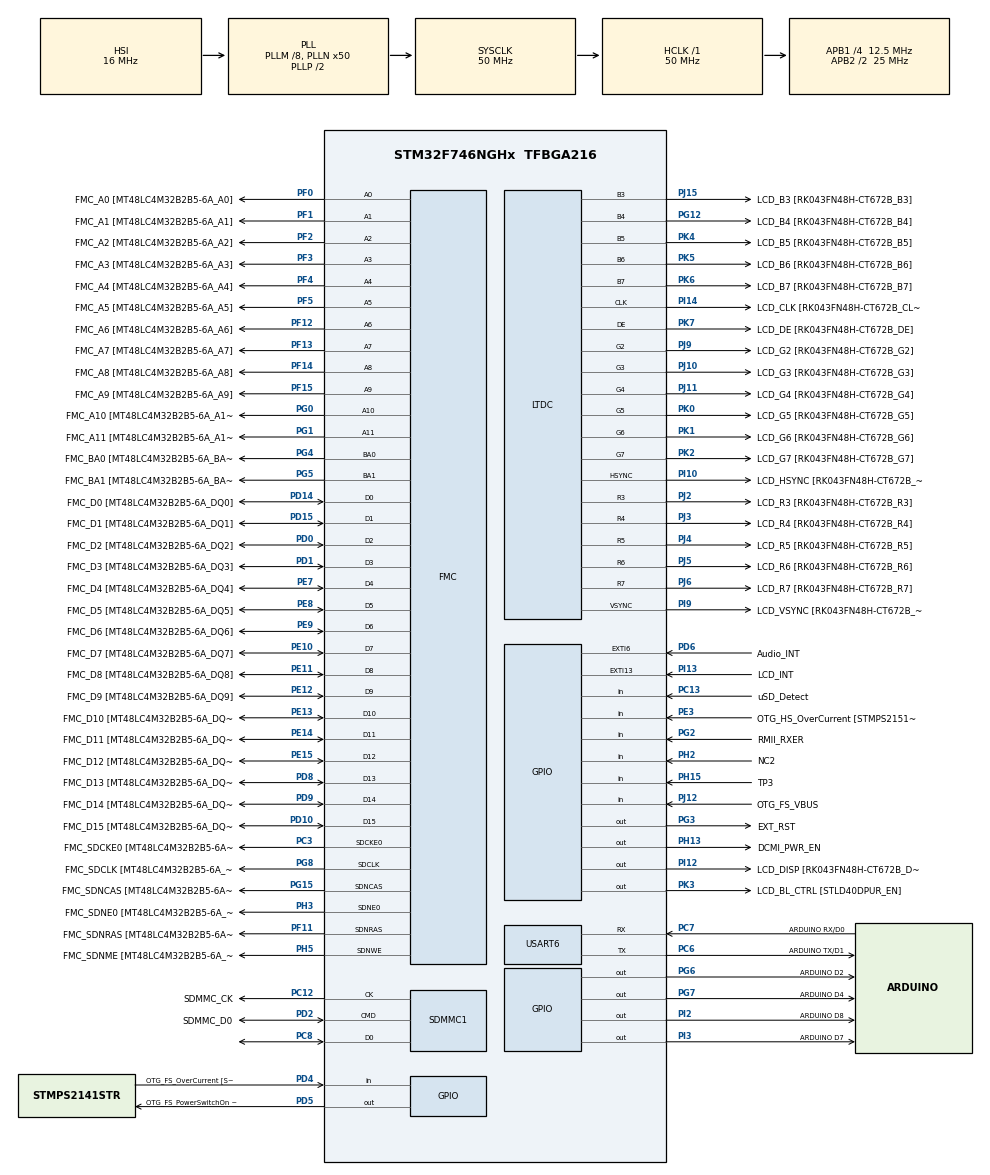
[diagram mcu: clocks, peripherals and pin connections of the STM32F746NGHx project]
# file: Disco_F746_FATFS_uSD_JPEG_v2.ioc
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Dma.Request0=SDMMC1_RX
Dma.Request1=SDMMC1_TX
Dma.SDMMC1_RX.0.Direction=DMA_PERIPH_TO_MEMORY
Dma.SDMMC1_RX.0.FIFOMode=DMA_FIFOMODE_ENABLE
Dma.SDMMC1_RX.0.FIFOThreshold=DMA_FIFO_THRESHOLD_FULL
Dma.SDMMC1_RX.0.Instance=DMA2_Stream3
Dma.SDMMC1_RX.0.MemBurst=DMA_MBURST_INC4
Dma.SDMMC1_RX.0.MemDataAlignment=DMA_MDATAALIGN_WORD
Dma.SDMMC1_RX.0.MemInc=DMA_MINC_ENABLE
Dma.SDMMC1_RX.0.Mode=DMA_PFCTRL
Dma.SDMMC1_RX.0.PeriphBurst=DMA_PBURST_INC4
Dma.SDMMC1_RX.0.PeriphDataAlignment=DMA_PDATAALIGN_WORD
Dma.SDMMC1_RX.0.PeriphInc=DMA_PINC_DISABLE
Dma.SDMMC1_RX.0.Priority=DMA_PRIORITY_LOW
Dma.SDMMC1_TX.1.Direction=DMA_MEMORY_TO_PERIPH
Dma.SDMMC1_TX.1.FIFOMode=DMA_FIFOMODE_ENABLE
Dma.SDMMC1_TX.1.FIFOThreshold=DMA_FIFO_THRESHOLD_FULL
Dma.SDMMC1_TX.1.Instance=DMA2_Stream6
Dma.SDMMC1_TX.1.MemBurst=DMA_MBURST_INC4
Dma.SDMMC1_TX.1.MemDataAlignment=DMA_MDATAALIGN_WORD
Dma.SDMMC1_TX.1.MemInc=DMA_MINC_ENABLE
Dma.SDMMC1_TX.1.Mode=DMA_PFCTRL
Dma.SDMMC1_TX.1.PeriphBurst=DMA_PBURST_INC4
Dma.SDMMC1_TX.1.PeriphDataAlignment=DMA_PDATAALIGN_WORD
Dma.SDMMC1_TX.1.PeriphInc=DMA_PINC_DISABLE
Dma.SDMMC1_TX.1.Priority=DMA_PRIORITY_LOW
FATFS.BSP.number=1
FATFS.USE_DMA_CODE_SD=1
FATFS0.BSP.STBoard=false
FATFS0.BSP.api=Unknown
FATFS0.BSP.instance=PC13
FATFS0.BSP.ip=GPIO
FATFS0.BSP.mode=Input
FATFS0.BSP.name=Detect_SDIO
FATFS0.BSP.solution=PC13
FMC.CASLatency1=FMC_SDRAM_CAS_LATENCY_3
FMC.ExitSelfRefreshDelay1=7
FMC.LoadToActiveDelay1=2
FMC.RCDDelay1=2
FMC.RPDelay1=2
FMC.RPDelay2=2
FMC.ReadBurst1=FMC_SDRAM_RBURST_ENABLE
FMC.ReadBurst2=FMC_SDRAM_RBURST_ENABLE
FMC.RowCycleDelay1=7
FMC.RowCycleDelay2=7
FMC.SDClockPeriod1=FMC_SDRAM_CLOCK_PERIOD_2
FMC.SDClockPeriod2=FMC_SDRAM_CLOCK_PERIOD_2
FMC.SelfRefreshTime1=4
FMC.WriteRecoveryTime1=3
Mcu.Family=STM32F7
Mcu.Name=STM32F746NGHx
Mcu.Package=TFBGA216
NVIC.DMA2_Stream3_IRQn=true\:0\:0\:false\:false\:true\:false\:true\:true
NVIC.DMA2_Stream6_IRQn=true\:0\:0\:false\:false\:true\:false\:true\:true
NVIC.PriorityGroup=NVIC_PRIORITYGROUP_4
NVIC.SDMMC1_IRQn=true\:0\:0\:false\:false\:true\:true\:true\:true
PA0/WKUP.GPIO_Label=ARDUINO A0
PA0/WKUP.GPIO_Mode=GPIO_MODE_ANALOG
PA0/WKUP.GPIO_PuPd=GPIO_NOPULL
PA0/WKUP.Signal=ADCx_IN0
PA1.GPIO_Label=RMII_REF_CLK [LAN8742A-CZ-TR_REFCLK0]
PA1.Signal=ETH_REF_CLK
PA10.GPIO_Label=OTG_FS_ID
PA10.Signal=USB_OTG_FS_ID
PA11.GPIO_Label=OTG_FS_N
PA11.Signal=USB_OTG_FS_DM
PA12.GPIO_Label=OTG_FS_P
PA12.Signal=USB_OTG_FS_DP
PA13.GPIO_Label=SWDIO
PA13.Signal=SYS_JTMS-SWDIO
PA14.GPIO_Label=SWCLK
PA14.Signal=SYS_JTCK-SWCLK
PA15.GPIO_Label=ARDUINO PWM/D9
PA15.GPIO_ModeDefaultPP=GPIO_MODE_AF_PP
PA15.GPIO_PuPd=GPIO_NOPULL
PA15.GPIO_Speed=GPIO_SPEED_FREQ_LOW
PA15.Signal=S_TIM2_CH1_ETR
PA2.GPIO_Label=RMII_MDIO [LAN8742A-CZ-TR_MDIO]
PA2.Signal=ETH_MDIO
PA3.GPIO_Label=ULPI_D0 [USB3320C-EZK_D0]
PA3.Signal=USB_OTG_HS_ULPI_D0
PA4.GPIO_Label=DCMI_HSYNC
PA4.Signal=DCMI_HSYNC
PA5.GPIO_Label=ULPI_CLK [USB3320C-EZK_CLKOUT]
PA5.Signal=USB_OTG_HS_ULPI_CK
PA6.Signal=DCMI_PIXCLK
PA7.GPIO_Label=RMII_CRS_DV [LAN8742A-CZ-TR_CRS_DV]
PA7.Signal=ETH_CRS_DV
PA8.GPIO_Label=ARDUINO PWM/D10
PA8.GPIO_ModeDefaultPP=GPIO_MODE_AF_PP
PA8.GPIO_PuPd=GPIO_NOPULL
PA8.GPIO_Speed=GPIO_SPEED_FREQ_LOW
PA8.Signal=S_TIM1_CH1
PA9.GPIO_Label=VCP_TX [STM32F103CBT6_PA3]
PA9.GPIO_Mode=GPIO_MODE_AF_PP
PA9.GPIO_PuPd=GPIO_NOPULL
PA9.GPIO_Speed=GPIO_SPEED_FREQ_LOW
PA9.Signal=USART1_TX
PB0.GPIO_Label=ULPI_D1 [USB3320C-EZK_D1]
PB0.Signal=USB_OTG_HS_ULPI_D1
PB1.GPIO_Label=ULPI_D2 [USB3320C-EZK_D2]
PB1.Signal=USB_OTG_HS_ULPI_D2
PB10.GPIO_Label=ULPI_D3 [USB3320C-EZK_D3]
PB10.Signal=USB_OTG_HS_ULPI_D3
PB11.GPIO_Label=ULPI_D4 [USB3320C-EZK_D4]
PB11.Signal=USB_OTG_HS_ULPI_D4
PB12.GPIO_Label=ULPI_D5 [USB3320C-EZK_D5]
PB12.Signal=USB_OTG_HS_ULPI_D5
PB13.GPIO_Label=ULPI_D6 [USB3320C-EZK_D6]
PB13.Signal=USB_OTG_HS_ULPI_D6
PB14.GPIO_Label=ARDUINO MISO/D12
PB14.GPIO_Mode=GPIO_MODE_AF_PP
PB14.GPIO_PuPd=GPIO_NOPULL
PB14.GPIO_Speed=GPIO_SPEED_FREQ_LOW
PB14.Signal=SPI2_MISO
PB15.GPIO_Label=ARDUINO MOSI/PWM/D11
PB15.GPIO_Mode=GPIO_MODE_AF_PP
PB15.GPIO_PuPd=GPIO_NOPULL
PB15.GPIO_Speed=GPIO_SPEED_FREQ_LOW
PB15.Signal=SPI2_MOSI
PB2.Signal=QUADSPI_CLK
PB3.GPIO_Label=SWO
PB3.Signal=SYS_JTDO-SWO
PB4.GPIO_Label=ARDUINO PWM/D3
PB4.GPIO_ModeDefaultPP=GPIO_MODE_AF_PP
PB4.GPIO_PuPd=GPIO_NOPULL
PB4.GPIO_Speed=GPIO_SPEED_FREQ_LOW
PB4.Signal=S_TIM3_CH1
PB5.GPIO_Label=ULPI_D7 [USB3320C-EZK_D7]
PB5.Signal=USB_OTG_HS_ULPI_D7
PB6.GPIO_Label=QSPI_NCS [N25Q128A13EF840E_S]
PB6.Signal=QUADSPI_BK1_NCS
PB7.GPIO_Label=VCP_RX [STM32F103CBT6_PA2]
PB7.GPIO_Mode=GPIO_MODE_AF_PP
PB7.GPIO_PuPd=GPIO_NOPULL
PB7.GPIO_Speed=GPIO_SPEED_FREQ_LOW
PB7.Signal=USART1_RX
PB8.GPIO_Label=ARDUINO SCL/D15
PB8.GPIO_Mode=GPIO_MODE_AF_OD
PB8.GPIO_PuPd=GPIO_NOPULL
PB8.GPIO_Speed=GPIO_SPEED_FREQ_LOW
PB8.Signal=I2C1_SCL
PB9.GPIO_Label=ARDUINO SDA/D14
PB9.GPIO_Mode=GPIO_MODE_AF_OD
PB9.GPIO_PuPd=GPIO_NOPULL
PB9.GPIO_Speed=GPIO_SPEED_FREQ_LOW
PB9.Signal=I2C1_SDA
PC0.GPIO_Label=ULPI_STP [USB3320C-EZK_STP]
PC0.Signal=USB_OTG_HS_ULPI_STP
PC1.GPIO_Label=RMII_MDC [LAN8742A-CZ-TR_MDC]
PC1.Signal=ETH_MDC
PC10.GPIO_Label=SDMMC_D2
PC10.Signal=SDMMC1_D2
PC11.GPIO_Label=SDMMC_D3
PC11.Signal=SDMMC1_D3
PC12.GPIO_Label=SDMMC_CK
PC12.GPIO_PuPd=GPIO_PULLUP
PC12.Mode=SD_1_bit
PC12.Signal=SDMMC1_CK
PC13.GPIO_Label=uSD_Detect
PC13.Signal=GPIO_Input
PC14/OSC32_IN.GPIO_Label=RCC_OSC32_IN
PC14/OSC32_IN.Signal=RCC_OSC32_IN
PC15/OSC32_OUT.GPIO_Label=RCC_OSC32_OUT
PC15/OSC32_OUT.Signal=RCC_OSC32_OUT
PC2.GPIO_Label=ULPI_DIR [USB3320C-EZK_DIR]
PC2.Signal=USB_OTG_HS_ULPI_DIR
PC3.GPIO_Label=FMC_SDCKE0 [MT48LC4M32B2B5-6A_CKE]
PC3.Mode=SdramChipSelect1_1
PC3.Signal=FMC_SDCKE0
PC4.GPIO_Label=RMII_RXD0 [LAN8742A-CZ-TR_RXD0]
PC4.Signal=ETH_RXD0
PC5.GPIO_Label=RMII_RXD1 [LAN8742A-CZ-TR_RXD1]
PC5.Signal=ETH_RXD1
PC6.GPIO_Label=ARDUINO TX/D1
PC6.Mode=Asynchronous
PC6.Signal=USART6_TX
PC7.GPIO_Label=ARDUINO RX/D0
PC7.Mode=Asynchronous
PC7.Signal=USART6_RX
PC8.GPIO_PuPd=GPIO_PULLUP
PC8.Mode=SD_1_bit
PC8.Signal=SDMMC1_D0
PC9.Signal=SDMMC1_D1
PD0.GPIO_Label=FMC_D2 [MT48LC4M32B2B5-6A_DQ2]
PD0.Signal=FMC_D2_DA2
PD1.GPIO_Label=FMC_D3 [MT48LC4M32B2B5-6A_DQ3]
PD1.Signal=FMC_D3_DA3
PD10.GPIO_Label=FMC_D15 [MT48LC4M32B2B5-6A_DQ15]
PD10.Signal=FMC_D15_DA15
PD11.GPIO_Label=QSPI_D0 [N25Q128A13EF840E_DQ0]
PD11.Signal=QUADSPI_BK1_IO0
PD12.GPIO_Label=QSPI_D1 [N25Q128A13EF840E_DQ1]
PD12.Signal=QUADSPI_BK1_IO1
PD13.GPIO_Label=QSPI_D3 [N25Q128A13EF840E_DQ3]
PD13.Signal=QUADSPI_BK1_IO3
PD14.GPIO_Label=FMC_D0 [MT48LC4M32B2B5-6A_DQ0]
PD14.Signal=FMC_D0_DA0
PD15.GPIO_Label=FMC_D1 [MT48LC4M32B2B5-6A_DQ1]
PD15.Signal=FMC_D1_DA1
PD2.GPIO_Label=SDMMC_D0
PD2.GPIO_PuPd=GPIO_PULLUP
PD2.Mode=SD_1_bit
PD2.Signal=SDMMC1_CMD
PD3.GPIO_Label=DCMI_D5
PD3.Signal=DCMI_D5
PD4.GPIO_Label=OTG_FS_OverCurrent [STMPS2141STR_Fault]
PD4.Signal=GPIO_Input
PD5.GPIO_Label=OTG_FS_PowerSwitchOn [STMPS2141STR_EN]
PD5.PinState=GPIO_PIN_SET
PD5.Signal=GPIO_Output
PD6.GPIO_Label=Audio_INT
PD6.GPIO_ModeDefaultEXTI=GPIO_MODE_EVT_RISING
PD6.Signal=GPXTI6
PD7.GPIO_Label=SPDIF_RX0 [74LVC1G04SE_4]
PD7.Signal=SPDIFRX_IN0
PD8.GPIO_Label=FMC_D13 [MT48LC4M32B2B5-6A_DQ13]
PD8.Signal=FMC_D13_DA13
PD9.GPIO_Label=FMC_D14 [MT48LC4M32B2B5-6A_DQ14]
PD9.Signal=FMC_D14_DA14
PE0.GPIO_Label=FMC_NBL0 [MT48LC4M32B2B5-6A_DQM0]
PE0.Signal=FMC_NBL0
PE1.GPIO_Label=FMC_NBL1 [MT48LC4M32B2B5-6A_DQM1]
PE1.Signal=FMC_NBL1
PE10.GPIO_Label=FMC_D7 [MT48LC4M32B2B5-6A_DQ7]
PE10.Signal=FMC_D7_DA7
PE11.GPIO_Label=FMC_D8 [MT48LC4M32B2B5-6A_DQ8]
PE11.Signal=FMC_D8_DA8
PE12.GPIO_Label=FMC_D9 [MT48LC4M32B2B5-6A_DQ9]
PE12.Signal=FMC_D9_DA9
PE13.GPIO_Label=FMC_D10 [MT48LC4M32B2B5-6A_DQ10]
PE13.Signal=FMC_D10_DA10
PE14.GPIO_Label=FMC_D11 [MT48LC4M32B2B5-6A_DQ11]
PE14.Signal=FMC_D11_DA11
PE15.GPIO_Label=FMC_D12 [MT48LC4M32B2B5-6A_DQ12]
PE15.Signal=FMC_D12_DA12
PE2.GPIO_Label=QSPI_D2 [N25Q128A13EF840E_DQ2]
PE2.Signal=QUADSPI_BK1_IO2
PE3.GPIO_Label=OTG_HS_OverCurrent [STMPS2151STR_FAULT]
PE3.Signal=GPIO_Input
PE4.GPIO_Label=LCD_B0 [RK043FN48H-CT672B_B0]
PE4.Signal=LTDC_B0
PE5.GPIO_Label=DCMI_D6
PE5.Signal=DCMI_D6
PE6.GPIO_Label=DCMI_D7
PE6.Signal=DCMI_D7
PE7.GPIO_Label=FMC_D4 [MT48LC4M32B2B5-6A_DQ4]
PE7.Signal=FMC_D4_DA4
PE8.GPIO_Label=FMC_D5 [MT48LC4M32B2B5-6A_DQ5]
PE8.Signal=FMC_D5_DA5
PE9.GPIO_Label=FMC_D6 [MT48LC4M32B2B5-6A_DQ6]
PE9.Signal=FMC_D6_DA6
PF0.GPIO_Label=FMC_A0 [MT48LC4M32B2B5-6A_A0]
PF0.Signal=FMC_A0
PF1.GPIO_Label=FMC_A1 [MT48LC4M32B2B5-6A_A1]
PF1.Signal=FMC_A1
PF10.GPIO_Label=ARDUINO A1
PF10.GPIO_Mode=GPIO_MODE_ANALOG
PF10.GPIO_PuPd=GPIO_NOPULL
PF10.Signal=ADC3_IN8
PF11.GPIO_Label=FMC_SDNRAS [MT48LC4M32B2B5-6A_RAS]
PF11.Signal=FMC_SDNRAS
PF12.GPIO_Label=FMC_A6 [MT48LC4M32B2B5-6A_A6]
PF12.Signal=FMC_A6
PF13.GPIO_Label=FMC_A7 [MT48LC4M32B2B5-6A_A7]
PF13.Signal=FMC_A7
PF14.GPIO_Label=FMC_A8 [MT48LC4M32B2B5-6A_A8]
PF14.Signal=FMC_A8
PF15.GPIO_Label=FMC_A9 [MT48LC4M32B2B5-6A_A9]
PF15.Signal=FMC_A9
PF2.GPIO_Label=FMC_A2 [MT48LC4M32B2B5-6A_A2]
PF2.Signal=FMC_A2
PF3.GPIO_Label=FMC_A3 [MT48LC4M32B2B5-6A_A3]
PF3.Signal=FMC_A3
PF4.GPIO_Label=FMC_A4 [MT48LC4M32B2B5-6A_A4]
PF4.Signal=FMC_A4
PF5.GPIO_Label=FMC_A5 [MT48LC4M32B2B5-6A_A5]
PF5.Signal=FMC_A5
PF6.GPIO_Label=ARDUINO A5
PF6.GPIO_Mode=GPIO_MODE_ANALOG
PF6.GPIO_PuPd=GPIO_NOPULL
PF6.Signal=ADC3_IN4
PF7.GPIO_Label=ARDUINO A4
PF7.GPIO_Mode=GPIO_MODE_ANALOG
PF7.GPIO_PuPd=GPIO_NOPULL
PF7.Signal=ADC3_IN5
PF8.GPIO_Label=ARDUINO A3
PF8.GPIO_Mode=GPIO_MODE_ANALOG
PF8.GPIO_PuPd=GPIO_NOPULL
PF8.Signal=ADC3_IN6
PF9.GPIO_Label=ARDUINO A2
PF9.GPIO_Mode=GPIO_MODE_ANALOG
PF9.GPIO_PuPd=GPIO_NOPULL
PF9.Signal=ADC3_IN7
PG0.GPIO_Label=FMC_A10 [MT48LC4M32B2B5-6A_A10]
PG0.Signal=FMC_A10
PG1.GPIO_Label=FMC_A11 [MT48LC4M32B2B5-6A_A11]
PG1.Signal=FMC_A11
PG10.GPIO_Label=SAI2_SDB [WM8994ECS/R_ADCDAT1]
PG10.Signal=SAI2_SD_B
PG11.GPIO_Label=RMII_TX_EN [LAN8742A-CZ-TR_TXEN]
PG11.Signal=ETH_TX_EN
PG12.GPIO_Label=LCD_B4 [RK043FN48H-CT672B_B4]
PG12.Mode=RGB565
PG12.Signal=LTDC_B4
PG13.GPIO_Label=RMII_TXD0 [LAN8742A-CZ-TR_TXD0]
PG13.Signal=ETH_TXD0
PG14.GPIO_Label=RMII_TXD1 [LAN8742A-CZ-TR_TXD1]
PG14.Signal=ETH_TXD1
PG15.GPIO_Label=FMC_SDNCAS [MT48LC4M32B2B5-6A_CAS]
PG15.Signal=FMC_SDNCAS
PG2.GPIO_Label=RMII_RXER
PG2.Signal=GPIO_Input
PG3.GPIO_Label=EXT_RST
PG3.Signal=GPIO_Output
PG4.GPIO_Label=FMC_BA0 [MT48LC4M32B2B5-6A_BA0]
PG4.Signal=FMC_A14_BA0
PG5.GPIO_Label=FMC_BA1 [MT48LC4M32B2B5-6A_BA1]
PG5.Signal=FMC_A15_BA1
PG6.GPIO_Label=ARDUINO D2
PG6.Signal=GPIO_Output
PG7.GPIO_Label=ARDUINO D4
PG7.Signal=GPIO_Output
PG8.GPIO_Label=FMC_SDCLK [MT48LC4M32B2B5-6A_CLK]
PG8.Signal=FMC_SDCLK
PG9.GPIO_Label=DCMI_VSYNC
PG9.Signal=DCMI_VSYNC
PH0/OSC_IN.GPIO_Label=OSC_25M [NZ2520SB-25.00M_OUT]
PH0/OSC_IN.Signal=RCC_OSC_IN
PH1/OSC_OUT.Signal=RCC_OSC_OUT
PH10.GPIO_Label=DCMI_D1
PH10.Signal=DCMI_D1
PH11.GPIO_Label=DCMI_D2
PH11.Signal=DCMI_D2
PH12.GPIO_Label=DCMI_D3
PH12.Signal=DCMI_D3
PH13.GPIO_Label=DCMI_PWR_EN
PH13.Signal=GPIO_Output
PH14.GPIO_Label=DCMI_D4
PH14.Signal=DCMI_D4
PH15.GPIO_Label=TP3
PH15.Signal=GPIO_Input
PH2.GPIO_Label=NC2
PH2.Signal=GPIO_Input
PH3.GPIO_Label=FMC_SDNE0 [MT48LC4M32B2B5-6A_CS]
PH3.Mode=SdramChipSelect1_1
PH3.Signal=FMC_SDNE0
PH4.GPIO_Label=ULPI_NXT [USB3320C-EZK_NXT]
PH4.Signal=USB_OTG_HS_ULPI_NXT
PH5.GPIO_Label=FMC_SDNME [MT48LC4M32B2B5-6A_WE]
PH5.Signal=FMC_SDNWE
PH6.GPIO_Label=ARDUINO PWM/D6
PH6.Signal=S_TIM12_CH1
PH7.GPIO_Label=LCD_SCL [RK043FN48H-CT672B_SCL]
PH7.Signal=I2C3_SCL
PH8.GPIO_Label=LCD_SDA [RK043FN48H-CT672B_SDA]
PH8.Signal=I2C3_SDA
PH9.GPIO_Label=DCMI_D0
PH9.Signal=DCMI_D0
PI0.GPIO_Label=ARDUINO PWM/CS/D5
PI0.GPIO_ModeDefaultPP=GPIO_MODE_AF_PP
PI0.GPIO_PuPd=GPIO_NOPULL
PI0.GPIO_Speed=GPIO_SPEED_FREQ_LOW
PI0.Signal=S_TIM5_CH4
PI1.GPIO_Label=ARDUINO SCK/D13
PI1.GPIO_Mode=GPIO_MODE_AF_PP
PI1.GPIO_PuPd=GPIO_NOPULL
PI1.GPIO_Speed=GPIO_SPEED_FREQ_LOW
PI1.Signal=SPI2_SCK
PI10.GPIO_Label=LCD_HSYNC [RK043FN48H-CT672B_HSYNC]
PI10.Mode=RGB565
PI10.Signal=LTDC_HSYNC
PI12.GPIO_Label=LCD_DISP [RK043FN48H-CT672B_DISP] 
PI12.Signal=GPIO_Output
PI13.GPIO_Label=LCD_INT
PI13.GPIO_ModeDefaultEXTI=GPIO_MODE_EVT_RISING
PI13.Signal=GPXTI13
PI14.GPIO_Label=LCD_CLK [RK043FN48H-CT672B_CLK]
PI14.Mode=RGB565
PI14.Signal=LTDC_CLK
PI15.GPIO_Label=LCD_R0 [RK043FN48H-CT672B_R0]
PI15.Signal=LTDC_R0
PI2.GPIO_Label=ARDUINO D8
PI2.Signal=GPIO_Output
PI3.GPIO_Label=ARDUINO D7
PI3.Signal=GPIO_Output
PI4.GPIO_Label=SAI2_MCLKA [WM8994ECS/R_MCLK1]
PI4.Signal=SAI2_MCLK_A
PI5.GPIO_Label=SAI2_SCKA [WM8994ECS/R_BCLK1]
PI5.Signal=SAI2_SCK_A
PI6.GPIO_Label=SAI2_SDA [WM8994ECS/R_DACDAT1]
PI6.Signal=SAI2_SD_A
PI7.GPIO_Label=SAI2_FSA [WM8994ECS/R_LRCLK1]
PI7.Signal=SAI2_FS_A
PI8.GPIO_Label=NC1 [TP2]
PI8.Signal=RTC_TS
PI9.GPIO_Label=LCD_VSYNC [RK043FN48H-CT672B_VSYNC]
PI9.Mode=RGB565
PI9.Signal=LTDC_VSYNC
PJ0.GPIO_Label=LCD_R1 [RK043FN48H-CT672B_R1]
PJ0.Signal=LTDC_R1
PJ1.GPIO_Label=LCD_R2 [RK043FN48H-CT672B_R2]
PJ1.Signal=LTDC_R2
PJ10.GPIO_Label=LCD_G3 [RK043FN48H-CT672B_G3]
PJ10.Mode=RGB565
PJ10.Signal=LTDC_G3
PJ11.GPIO_Label=LCD_G4 [RK043FN48H-CT672B_G4]
PJ11.Mode=RGB565
PJ11.Signal=LTDC_G4
PJ12.GPIO_Label=OTG_FS_VBUS
PJ12.Signal=GPIO_Input
PJ13.GPIO_Label=LCD_B1 [RK043FN48H-CT672B_B1]
PJ13.Signal=LTDC_B1
PJ14.GPIO_Label=LCD_B2 [RK043FN48H-CT672B_B2]
PJ14.Signal=LTDC_B2
PJ15.GPIO_Label=LCD_B3 [RK043FN48H-CT672B_B3]
PJ15.Mode=RGB565
PJ15.Signal=LTDC_B3
PJ2.GPIO_Label=LCD_R3 [RK043FN48H-CT672B_R3]
PJ2.Mode=RGB565
PJ2.Signal=LTDC_R3
PJ3.GPIO_Label=LCD_R4 [RK043FN48H-CT672B_R4]
PJ3.Mode=RGB565
PJ3.Signal=LTDC_R4
PJ4.GPIO_Label=LCD_R5 [RK043FN48H-CT672B_R5]
PJ4.Mode=RGB565
PJ4.Signal=LTDC_R5
PJ5.GPIO_Label=LCD_R6 [RK043FN48H-CT672B_R6]
PJ5.Mode=RGB565
PJ5.Signal=LTDC_R6
PJ6.GPIO_Label=LCD_R7 [RK043FN48H-CT672B_R7]
PJ6.Mode=RGB565
PJ6.Signal=LTDC_R7
PJ7.GPIO_Label=LCD_G0 [RK043FN48H-CT672B_G0]
PJ7.Signal=LTDC_G0
PJ8.GPIO_Label=LCD_G1 [RK043FN48H-CT672B_G1]
PJ8.Signal=LTDC_G1
PJ9.GPIO_Label=LCD_G2 [RK043FN48H-CT672B_G2]
PJ9.Mode=RGB565
PJ9.Signal=LTDC_G2
PK0.GPIO_Label=LCD_G5 [RK043FN48H-CT672B_G5]
PK0.Mode=RGB565
PK0.Signal=LTDC_G5
PK1.GPIO_Label=LCD_G6 [RK043FN48H-CT672B_G6]
PK1.Mode=RGB565
PK1.Signal=LTDC_G6
PK2.GPIO_Label=LCD_G7 [RK043FN48H-CT672B_G7]
PK2.Mode=RGB565
PK2.Signal=LTDC_G7
PK3.GPIO_Label=LCD_BL_CTRL [STLD40DPUR_EN]
PK3.Signal=GPIO_Output
PK4.GPIO_Label=LCD_B5 [RK043FN48H-CT672B_B5]
PK4.Mode=RGB565
PK4.Signal=LTDC_B5
PK5.GPIO_Label=LCD_B6 [RK043FN48H-CT672B_B6]
PK5.Mode=RGB565
PK5.Signal=LTDC_B6
PK6.GPIO_Label=LCD_B7 [RK043FN48H-CT672B_B7]
PK6.Mode=RGB565
PK6.Signal=LTDC_B7
PK7.GPIO_Label=LCD_DE [RK043FN48H-CT672B_DE]
PK7.Mode=RGB565
PK7.Signal=LTDC_DE
ProjectManager.HeapSize=0x800
ProjectManager.StackSize=0x1000
ProjectManager.TargetToolchain=STM32CubeIDE
RCC.AHBFreq_Value=50000000
RCC.APB1CLKDivider=RCC_HCLK_DIV4
RCC.APB1Freq_Value=12500000
RCC.APB1TimFreq_Value=25000000
RCC.APB2CLKDivider=RCC_HCLK_DIV2
RCC.APB2Freq_Value=25000000
RCC.APB2TimFreq_Value=50000000
RCC.CortexFreq_Value=50000000
RCC.HCLKFreq_Value=50000000
RCC.HSE_VALUE=25000000
RCC.HSI_VALUE=16000000
RCC.LSE_VALUE=32768
RCC.PLLM=8
RCC.PLLN=50
RCC.PLLSAIN=50
RCC.PLLSourceVirtual=RCC_PLLSOURCE_HSI
RCC.SYSCLKFreq_VALUE=50000000
RCC.SYSCLKSource=RCC_SYSCLKSOURCE_PLLCLK
RCC.USBFreq_Value=50000000
RCC.VCOOutputFreq_Value=100000000
SH.ADCx_IN0.0=ADC3_IN0
SH.FMC_A0.0=FMC_A0,12b-sda1
SH.FMC_A1.0=FMC_A1,12b-sda1
SH.FMC_A10.0=FMC_A10,12b-sda1
SH.FMC_A11.0=FMC_A11,12b-sda1
SH.FMC_A14_BA0.0=FMC_BA0,FourSdramBanks1
SH.FMC_A15_BA1.0=FMC_BA1,FourSdramBanks1
SH.FMC_A2.0=FMC_A2,12b-sda1
SH.FMC_A3.0=FMC_A3,12b-sda1
SH.FMC_A4.0=FMC_A4,12b-sda1
SH.FMC_A5.0=FMC_A5,12b-sda1
SH.FMC_A6.0=FMC_A6,12b-sda1
SH.FMC_A7.0=FMC_A7,12b-sda1
SH.FMC_A8.0=FMC_A8,12b-sda1
SH.FMC_A9.0=FMC_A9,12b-sda1
SH.FMC_D0_DA0.0=FMC_D0,sd-16b-d1
SH.FMC_D10_DA10.0=FMC_D10,sd-16b-d1
SH.FMC_D11_DA11.0=FMC_D11,sd-16b-d1
SH.FMC_D12_DA12.0=FMC_D12,sd-16b-d1
SH.FMC_D13_DA13.0=FMC_D13,sd-16b-d1
SH.FMC_D14_DA14.0=FMC_D14,sd-16b-d1
SH.FMC_D15_DA15.0=FMC_D15,sd-16b-d1
SH.FMC_D1_DA1.0=FMC_D1,sd-16b-d1
SH.FMC_D2_DA2.0=FMC_D2,sd-16b-d1
SH.FMC_D3_DA3.0=FMC_D3,sd-16b-d1
SH.FMC_D4_DA4.0=FMC_D4,sd-16b-d1
SH.FMC_D5_DA5.0=FMC_D5,sd-16b-d1
SH.FMC_D6_DA6.0=FMC_D6,sd-16b-d1
SH.FMC_D7_DA7.0=FMC_D7,sd-16b-d1
SH.FMC_D8_DA8.0=FMC_D8,sd-16b-d1
SH.FMC_D9_DA9.0=FMC_D9,sd-16b-d1
SH.FMC_NBL0.0=FMC_NBL0
SH.FMC_NBL1.0=FMC_NBL1
SH.FMC_SDCLK.0=FMC_SDCLK,12b-sda1
SH.FMC_SDNCAS.0=FMC_SDNCAS,12b-sda1
SH.FMC_SDNRAS.0=FMC_SDNRAS,12b-sda1
SH.FMC_SDNWE.0=FMC_SDNWE,12b-sda1
SH.S_TIM12_CH1.0=TIM12_CH1
SH.S_TIM1_CH1.0=TIM1_CH1
SH.S_TIM2_CH1_ETR.0=TIM2_CH1
SH.S_TIM3_CH1.0=TIM3_CH1
SH.S_TIM5_CH4.0=TIM5_CH4
USART6.VirtualMode-Asynchronous=VM_ASYNC
VP_DMA2D_VS_DMA2D.Mode=DMA2D_Activate
VP_FATFS_VS_SDIO.Mode=SDIO
VP_LIBJPEG_VS_JPEGLIB.Mode=Enabled
board=STM32F746G-DISCO

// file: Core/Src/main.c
/* USER CODE BEGIN Header */
/**
  ******************************************************************************
  * @file           : main.c
  * @brief          : Main program body
  ******************************************************************************
  * @attention
  *
  * <h2><center>&copy; Copyright (c) 2020 STMicroelectronics.
  * All rights reserved.</center></h2>
  *
  * This software component is licensed by ST under BSD 3-Clause license,
  * the "License"; You may not use this file except in compliance with the
  * License. You may obtain a copy of the License at:
  *                        opensource.org/licenses/BSD-3-Clause
  *
  ******************************************************************************
  */
/* USER CODE END Header */
#include "main.h"
#include "fatfs.h"
#include "libjpeg.h"

/* USER CODE BEGIN Includes */
#include "stm32746g_discovery.h"
#include "stm32746g_discovery_sdram.h"
#include "stm32746g_discovery_lcd.h"
//#include "ov5640.h"
#include "rk043fn48h.h"
#include "fonts.h"

#include <stdio.h>
#include <string.h>
/* USER CODE END Includes */

/* USER CODE BEGIN PTD */
  /* This struct contains the JPEG decompression parameters */
  struct jpeg_decompress_struct cinfo;
  /* This struct represents a JPEG error handler */
  struct jpeg_error_mgr jerr;

//  typedef struct
//  {
//  	uint32_t TextColor; uint32_t BackColor; sFONT *pFont;
//  }LCD_DrawPropTypeDef;

/* USER CODE END PTD */

/* USER CODE BEGIN PD */

#define SWAP_RB
#define USE_DMA2D
/* USER CODE END PD */

DMA2D_HandleTypeDef hdma2d;

LTDC_HandleTypeDef hltdc;

SD_HandleTypeDef hsd1;
DMA_HandleTypeDef hdma_sdmmc1_rx;
DMA_HandleTypeDef hdma_sdmmc1_tx;

UART_HandleTypeDef huart6;

SDRAM_HandleTypeDef hsdram1;

/* USER CODE BEGIN PV */

RGB_typedef *RGB_matrix;
uint8_t   _aucLine[2048];
uint32_t  offset = 0;
uint32_t line_counter = 239;

static LCD_DrawPropTypeDef DrawProp[2];
LTDC_HandleTypeDef hltdc;
LTDC_LayerCfgTypeDef layer_cfg;
static RCC_PeriphCLKInitTypeDef periph_clk_init_struct;

/* USER CODE END PV */

void SystemClock_Config(void);
static void MX_GPIO_Init(void);
static void MX_DMA_Init(void);
static void MX_SDMMC1_SD_Init(void);
static void MX_USART6_UART_Init(void);
static void MX_FMC_Init(void);
static void MX_LTDC_Init(void);
static void MX_DMA2D_Init(void);
/* USER CODE BEGIN PFP */

#define JFILE FIL
void jpeg_decode(JFILE *file, uint32_t width, uint8_t * buff, uint8_t (*callback)(uint8_t*, uint32_t));

static void LCD_Config(void);
static uint8_t Jpeg_CallbackFunction(uint8_t* Row, uint32_t DataLength);
void LCD_GPIO_Init(LTDC_HandleTypeDef *, void *);

/* USER CODE END PFP */

int main(void)
{

  /* MCU Configuration--------------------------------------------------------*/

  /* Reset of all peripherals, Initializes the Flash interface and the Systick. */
  HAL_Init();

  /* Configure the system clock */
  SystemClock_Config();

  /* Initialize all configured peripherals */
  MX_GPIO_Init();
  MX_DMA_Init();
  MX_SDMMC1_SD_Init();
  MX_FATFS_Init();
  MX_LIBJPEG_Init();
  MX_USART6_UART_Init();
  MX_FMC_Init();
  MX_LTDC_Init();
  MX_DMA2D_Init();
  /* USER CODE BEGIN 2 */

  /*##-1- LCD Configuration ##################################################*/
  LCD_Config();

  /*##-2- Link the micro SD disk I/O driver ##################################*/
 // if(FATFS_LinkDriver(&SD_Driver, SDPath) == 0)
  {
    /*##-3- Register the file system object to the FatFs module ##############*/
    if(f_mount(&SDFatFS, (TCHAR const*)SDPath, 0) == FR_OK)
    {
      /*##-4- Open the JPG image with read access ############################*/
       if(f_open(&SDFile, "image.jpg", FA_READ) == FR_OK)
       {
       }
     }
   }

  /*##-5- Decode the jpg image file ##########################################*/
  jpeg_decode(&SDFile, IMAGE_WIDTH, _aucLine, Jpeg_CallbackFunction);

  /*##-4- Close the JPG image ################################################*/
  f_close(&SDFile);

//	if(f_mount(&SDFatFS, (TCHAR const*)SDPath, 0) != FR_OK)
//	{
//		Error_Handler();
//	}
//	else
//	{
//		if(f_mkfs((TCHAR const*)SDPath, FM_ANY, 0, rtext, sizeof(rtext)) != FR_OK)
//	    {
//			Error_Handler();
//	    }
//		else
//		{
//			//Open file for writing (Create)
//			if(f_open(&SDFile, "STM32.TXT", FA_CREATE_ALWAYS | FA_WRITE) != FR_OK)
//			{
//				Error_Handler();
//			}
//			else
//			{
//
//				//Write to the text file
//				res = f_write(&SDFile, wtext, strlen((char *)wtext), (void *)&byteswritten);
//				if((byteswritten == 0) || (res != FR_OK))
//				{
//					Error_Handler();
//				}
//				else
//				{
//
//					f_close(&SDFile);
//				}
//			}
//		}
//	}
//	f_mount(&SDFatFS, (TCHAR const*)NULL, 0);
  /* USER CODE END 2 */

  /* Infinite loop */
  while (1)
  {

  }
}

void SystemClock_Config(void)
{
  RCC_OscInitTypeDef RCC_OscInitStruct = {0};
  RCC_ClkInitTypeDef RCC_ClkInitStruct = {0};

  /** Configure the main internal regulator output voltage
  */
  __HAL_RCC_PWR_CLK_ENABLE();
  __HAL_PWR_VOLTAGESCALING_CONFIG(PWR_REGULATOR_VOLTAGE_SCALE3);

  /** Initializes the RCC Oscillators according to the specified parameters
  * in the RCC_OscInitTypeDef structure.
  */
  RCC_OscInitStruct.OscillatorType = RCC_OSCILLATORTYPE_HSI;
  RCC_OscInitStruct.HSIState = RCC_HSI_ON;
  RCC_OscInitStruct.HSICalibrationValue = RCC_HSICALIBRATION_DEFAULT;
  RCC_OscInitStruct.PLL.PLLState = RCC_PLL_ON;
  RCC_OscInitStruct.PLL.PLLSource = RCC_PLLSOURCE_HSI;
  RCC_OscInitStruct.PLL.PLLM = 8;
  RCC_OscInitStruct.PLL.PLLN = 50;
  RCC_OscInitStruct.PLL.PLLP = RCC_PLLP_DIV2;
  RCC_OscInitStruct.PLL.PLLQ = 2;
  if (HAL_RCC_OscConfig(&RCC_OscInitStruct) != HAL_OK)
  {
    Error_Handler();
  }

  /** Initializes the CPU, AHB and APB buses clocks
  */
  RCC_ClkInitStruct.ClockType = RCC_CLOCKTYPE_HCLK|RCC_CLOCKTYPE_SYSCLK
                              |RCC_CLOCKTYPE_PCLK1|RCC_CLOCKTYPE_PCLK2;
  RCC_ClkInitStruct.SYSCLKSource = RCC_SYSCLKSOURCE_PLLCLK;
  RCC_ClkInitStruct.AHBCLKDivider = RCC_SYSCLK_DIV1;
  RCC_ClkInitStruct.APB1CLKDivider = RCC_HCLK_DIV4;
  RCC_ClkInitStruct.APB2CLKDivider = RCC_HCLK_DIV2;

  if (HAL_RCC_ClockConfig(&RCC_ClkInitStruct, FLASH_LATENCY_1) != HAL_OK)
  {
    Error_Handler();
  }
}

static void MX_DMA2D_Init(void)
{

  hdma2d.Instance = DMA2D;
  hdma2d.Init.Mode = DMA2D_M2M;
  hdma2d.Init.ColorMode = DMA2D_OUTPUT_ARGB8888;
  hdma2d.Init.OutputOffset = 0;
  hdma2d.LayerCfg[1].InputOffset = 0;
  hdma2d.LayerCfg[1].InputColorMode = DMA2D_INPUT_ARGB8888;
  hdma2d.LayerCfg[1].AlphaMode = DMA2D_NO_MODIF_ALPHA;
  hdma2d.LayerCfg[1].InputAlpha = 0;
  if (HAL_DMA2D_Init(&hdma2d) != HAL_OK)
  {
    Error_Handler();
  }
  if (HAL_DMA2D_ConfigLayer(&hdma2d, 1) != HAL_OK)
  {
    Error_Handler();
  }

}

static void MX_LTDC_Init(void)
{

  LTDC_LayerCfgTypeDef pLayerCfg = {0};
  LTDC_LayerCfgTypeDef pLayerCfg1 = {0};

  hltdc.Instance = LTDC;
  hltdc.Init.HSPolarity = LTDC_HSPOLARITY_AL;
  hltdc.Init.VSPolarity = LTDC_VSPOLARITY_AL;
  hltdc.Init.DEPolarity = LTDC_DEPOLARITY_AL;
  hltdc.Init.PCPolarity = LTDC_PCPOLARITY_IPC;
  hltdc.Init.HorizontalSync = 7;
  hltdc.Init.VerticalSync = 3;
  hltdc.Init.AccumulatedHBP = 14;
  hltdc.Init.AccumulatedVBP = 5;
  hltdc.Init.AccumulatedActiveW = 654;
  hltdc.Init.AccumulatedActiveH = 485;
  hltdc.Init.TotalWidth = 660;
  hltdc.Init.TotalHeigh = 487;
  hltdc.Init.Backcolor.Blue = 0;
  hltdc.Init.Backcolor.Green = 0;
  hltdc.Init.Backcolor.Red = 0;
  if (HAL_LTDC_Init(&hltdc) != HAL_OK)
  {
    Error_Handler();
  }
  pLayerCfg.WindowX0 = 0;
  pLayerCfg.WindowX1 = 0;
  pLayerCfg.WindowY0 = 0;
  pLayerCfg.WindowY1 = 0;
  pLayerCfg.PixelFormat = LTDC_PIXEL_FORMAT_ARGB8888;
  pLayerCfg.Alpha = 0;
  pLayerCfg.Alpha0 = 0;
  pLayerCfg.BlendingFactor1 = LTDC_BLENDING_FACTOR1_CA;
  pLayerCfg.BlendingFactor2 = LTDC_BLENDING_FACTOR2_CA;
  pLayerCfg.FBStartAdress = 0;
  pLayerCfg.ImageWidth = 0;
  pLayerCfg.ImageHeight = 0;
  pLayerCfg.Backcolor.Blue = 0;
  pLayerCfg.Backcolor.Green = 0;
  pLayerCfg.Backcolor.Red = 0;
  if (HAL_LTDC_ConfigLayer(&hltdc, &pLayerCfg, 0) != HAL_OK)
  {
    Error_Handler();
  }
  pLayerCfg1.WindowX0 = 0;
  pLayerCfg1.WindowX1 = 0;
  pLayerCfg1.WindowY0 = 0;
  pLayerCfg1.WindowY1 = 0;
  pLayerCfg1.PixelFormat = LTDC_PIXEL_FORMAT_ARGB8888;
  pLayerCfg1.Alpha = 0;
  pLayerCfg1.Alpha0 = 0;
  pLayerCfg1.BlendingFactor1 = LTDC_BLENDING_FACTOR1_CA;
  pLayerCfg1.BlendingFactor2 = LTDC_BLENDING_FACTOR2_CA;
  pLayerCfg1.FBStartAdress = 0;
  pLayerCfg1.ImageWidth = 0;
  pLayerCfg1.ImageHeight = 0;
  pLayerCfg1.Backcolor.Blue = 0;
  pLayerCfg1.Backcolor.Green = 0;
  pLayerCfg1.Backcolor.Red = 0;
  if (HAL_LTDC_ConfigLayer(&hltdc, &pLayerCfg1, 1) != HAL_OK)
  {
    Error_Handler();
  }

}

static void MX_SDMMC1_SD_Init(void)
{

  hsd1.Instance = SDMMC1;
  hsd1.Init.ClockEdge = SDMMC_CLOCK_EDGE_RISING;
  hsd1.Init.ClockBypass = SDMMC_CLOCK_BYPASS_DISABLE;
  hsd1.Init.ClockPowerSave = SDMMC_CLOCK_POWER_SAVE_DISABLE;
  hsd1.Init.BusWide = SDMMC_BUS_WIDE_1B;
  hsd1.Init.HardwareFlowControl = SDMMC_HARDWARE_FLOW_CONTROL_DISABLE;
  hsd1.Init.ClockDiv = 0;

}

static void MX_USART6_UART_Init(void)
{

  huart6.Instance = USART6;
  huart6.Init.BaudRate = 115200;
  huart6.Init.WordLength = UART_WORDLENGTH_8B;
  huart6.Init.StopBits = UART_STOPBITS_1;
  huart6.Init.Parity = UART_PARITY_NONE;
  huart6.Init.Mode = UART_MODE_TX_RX;
  huart6.Init.HwFlowCtl = UART_HWCONTROL_NONE;
  huart6.Init.OverSampling = UART_OVERSAMPLING_16;
  huart6.Init.OneBitSampling = UART_ONE_BIT_SAMPLE_DISABLE;
  huart6.AdvancedInit.AdvFeatureInit = UART_ADVFEATURE_NO_INIT;
  if (HAL_UART_Init(&huart6) != HAL_OK)
  {
    Error_Handler();
  }

}

static void MX_DMA_Init(void)
{

  /* DMA controller clock enable */
  __HAL_RCC_DMA2_CLK_ENABLE();

  /* DMA interrupt init */
  /* DMA2_Stream3_IRQn interrupt configuration */
  HAL_NVIC_SetPriority(DMA2_Stream3_IRQn, 0, 0);
  HAL_NVIC_EnableIRQ(DMA2_Stream3_IRQn);
  /* DMA2_Stream6_IRQn interrupt configuration */
  HAL_NVIC_SetPriority(DMA2_Stream6_IRQn, 0, 0);
  HAL_NVIC_EnableIRQ(DMA2_Stream6_IRQn);

}

/* FMC initialization function */
static void MX_FMC_Init(void)
{

  FMC_SDRAM_TimingTypeDef SdramTiming = {0};

  /** Perform the SDRAM1 memory initialization sequence
  */
  hsdram1.Instance = FMC_SDRAM_DEVICE;
  /* hsdram1.Init */
  hsdram1.Init.SDBank = FMC_SDRAM_BANK1;
  hsdram1.Init.ColumnBitsNumber = FMC_SDRAM_COLUMN_BITS_NUM_8;
  hsdram1.Init.RowBitsNumber = FMC_SDRAM_ROW_BITS_NUM_12;
  hsdram1.Init.MemoryDataWidth = FMC_SDRAM_MEM_BUS_WIDTH_16;
  hsdram1.Init.InternalBankNumber = FMC_SDRAM_INTERN_BANKS_NUM_4;
  hsdram1.Init.CASLatency = FMC_SDRAM_CAS_LATENCY_3;
  hsdram1.Init.WriteProtection = FMC_SDRAM_WRITE_PROTECTION_DISABLE;
  hsdram1.Init.SDClockPeriod = FMC_SDRAM_CLOCK_PERIOD_2;
  hsdram1.Init.ReadBurst = FMC_SDRAM_RBURST_ENABLE;
  hsdram1.Init.ReadPipeDelay = FMC_SDRAM_RPIPE_DELAY_0;
  /* SdramTiming */
  SdramTiming.LoadToActiveDelay = 2;
  SdramTiming.ExitSelfRefreshDelay = 7;
  SdramTiming.SelfRefreshTime = 4;
  SdramTiming.RowCycleDelay = 7;
  SdramTiming.WriteRecoveryTime = 3;
  SdramTiming.RPDelay = 2;
  SdramTiming.RCDDelay = 2;

  if (HAL_SDRAM_Init(&hsdram1, &SdramTiming) != HAL_OK)
  {
    Error_Handler( );
  }

}

static void MX_GPIO_Init(void)
{
  GPIO_InitTypeDef GPIO_InitStruct = {0};

  /* GPIO Ports Clock Enable */
  __HAL_RCC_GPIOE_CLK_ENABLE();
  __HAL_RCC_GPIOG_CLK_ENABLE();
  __HAL_RCC_GPIOB_CLK_ENABLE();
  __HAL_RCC_GPIOD_CLK_ENABLE();
  __HAL_RCC_GPIOC_CLK_ENABLE();
  __HAL_RCC_GPIOA_CLK_ENABLE();
  __HAL_RCC_GPIOJ_CLK_ENABLE();
  __HAL_RCC_GPIOI_CLK_ENABLE();
  __HAL_RCC_GPIOK_CLK_ENABLE();
  __HAL_RCC_GPIOF_CLK_ENABLE();
  __HAL_RCC_GPIOH_CLK_ENABLE();

  /*Configure GPIO pin Output Level */
  HAL_GPIO_WritePin(OTG_FS_PowerSwitchOn_GPIO_Port, OTG_FS_PowerSwitchOn_Pin, GPIO_PIN_SET);

  /*Configure GPIO pin Output Level */
  HAL_GPIO_WritePin(GPIOI, ARDUINO_D7_Pin|ARDUINO_D8_Pin|LCD_DISP_Pin, GPIO_PIN_RESET);

  /*Configure GPIO pin Output Level */
  HAL_GPIO_WritePin(LCD_BL_CTRL_GPIO_Port, LCD_BL_CTRL_Pin, GPIO_PIN_RESET);

  /*Configure GPIO pin Output Level */
  HAL_GPIO_WritePin(DCMI_PWR_EN_GPIO_Port, DCMI_PWR_EN_Pin, GPIO_PIN_RESET);

  /*Configure GPIO pin Output Level */
  HAL_GPIO_WritePin(GPIOG, ARDUINO_D4_Pin|ARDUINO_D2_Pin|EXT_RST_Pin, GPIO_PIN_RESET);

  /*Configure GPIO pin : OTG_HS_OverCurrent_Pin */
  GPIO_InitStruct.Pin = OTG_HS_OverCurrent_Pin;
  GPIO_InitStruct.Mode = GPIO_MODE_INPUT;
  GPIO_InitStruct.Pull = GPIO_NOPULL;
  HAL_GPIO_Init(OTG_HS_OverCurrent_GPIO_Port, &GPIO_InitStruct);

  /*Configure GPIO pin : QSPI_D2_Pin */
  GPIO_InitStruct.Pin = QSPI_D2_Pin;
  GPIO_InitStruct.Mode = GPIO_MODE_AF_PP;
  GPIO_InitStruct.Pull = GPIO_NOPULL;
  GPIO_InitStruct.Speed = GPIO_SPEED_FREQ_VERY_HIGH;
  GPIO_InitStruct.Alternate = GPIO_AF9_QUADSPI;
  HAL_GPIO_Init(QSPI_D2_GPIO_Port, &GPIO_InitStruct);

  /*Configure GPIO pins : RMII_TXD1_Pin RMII_TXD0_Pin RMII_TX_EN_Pin */
  GPIO_InitStruct.Pin = RMII_TXD1_Pin|RMII_TXD0_Pin|RMII_TX_EN_Pin;
  GPIO_InitStruct.Mode = GPIO_MODE_AF_PP;
  GPIO_InitStruct.Pull = GPIO_NOPULL;
  GPIO_InitStruct.Speed = GPIO_SPEED_FREQ_VERY_HIGH;
  GPIO_InitStruct.Alternate = GPIO_AF11_ETH;
  HAL_GPIO_Init(GPIOG, &GPIO_InitStruct);

  /*Configure GPIO pins : ARDUINO_SCL_D15_Pin ARDUINO_SDA_D14_Pin */
  GPIO_InitStruct.Pin = ARDUINO_SCL_D15_Pin|ARDUINO_SDA_D14_Pin;
  GPIO_InitStruct.Mode = GPIO_MODE_AF_OD;
  GPIO_InitStruct.Pull = GPIO_NOPULL;
  GPIO_InitStruct.Speed = GPIO_SPEED_FREQ_LOW;
  GPIO_InitStruct.Alternate = GPIO_AF4_I2C1;
  HAL_GPIO_Init(GPIOB, &GPIO_InitStruct);

  /*Configure GPIO pins : ULPI_D7_Pin ULPI_D6_Pin ULPI_D5_Pin ULPI_D3_Pin
                           ULPI_D2_Pin ULPI_D1_Pin ULPI_D4_Pin */
  GPIO_InitStruct.Pin = ULPI_D7_Pin|ULPI_D6_Pin|ULPI_D5_Pin|ULPI_D3_Pin
                          |ULPI_D2_Pin|ULPI_D1_Pin|ULPI_D4_Pin;
  GPIO_InitStruct.Mode = GPIO_MODE_AF_PP;
  GPIO_InitStruct.Pull = GPIO_NOPULL;
  GPIO_InitStruct.Speed = GPIO_SPEED_FREQ_VERY_HIGH;
  GPIO_InitStruct.Alternate = GPIO_AF10_OTG_HS;
  HAL_GPIO_Init(GPIOB, &GPIO_InitStruct);

  /*Configure GPIO pin : ARDUINO_PWM_D3_Pin */
  GPIO_InitStruct.Pin = ARDUINO_PWM_D3_Pin;
  GPIO_InitStruct.Mode = GPIO_MODE_AF_PP;
  GPIO_InitStruct.Pull = GPIO_NOPULL;
  GPIO_InitStruct.Speed = GPIO_SPEED_FREQ_LOW;
  GPIO_InitStruct.Alternate = GPIO_AF2_TIM3;
  HAL_GPIO_Init(ARDUINO_PWM_D3_GPIO_Port, &GPIO_InitStruct);

  /*Configure GPIO pin : SPDIF_RX0_Pin */
  GPIO_InitStruct.Pin = SPDIF_RX0_Pin;
  GPIO_InitStruct.Mode = GPIO_MODE_AF_PP;
  GPIO_InitStruct.Pull = GPIO_NOPULL;
  GPIO_InitStruct.Speed = GPIO_SPEED_FREQ_LOW;
  GPIO_InitStruct.Alternate = GPIO_AF8_SPDIFRX;
  HAL_GPIO_Init(SPDIF_RX0_GPIO_Port, &GPIO_InitStruct);

  /*Configure GPIO pin : ARDUINO_PWM_D9_Pin */
  GPIO_InitStruct.Pin = ARDUINO_PWM_D9_Pin;
  GPIO_InitStruct.Mode = GPIO_MODE_AF_PP;
  GPIO_InitStruct.Pull = GPIO_NOPULL;
  GPIO_InitStruct.Speed = GPIO_SPEED_FREQ_LOW;
  GPIO_InitStruct.Alternate = GPIO_AF1_TIM2;
  HAL_GPIO_Init(ARDUINO_PWM_D9_GPIO_Port, &GPIO_InitStruct);

  /*Configure GPIO pins : DCMI_D6_Pin DCMI_D7_Pin */
  GPIO_InitStruct.Pin = DCMI_D6_Pin|DCMI_D7_Pin;
  GPIO_InitStruct.Mode = GPIO_MODE_AF_PP;
  GPIO_InitStruct.Pull = GPIO_NOPULL;
  GPIO_InitStruct.Speed = GPIO_SPEED_FREQ_LOW;
  GPIO_InitStruct.Alternate = GPIO_AF13_DCMI;
  HAL_GPIO_Init(GPIOE, &GPIO_InitStruct);

  /*Configure GPIO pin : VCP_RX_Pin */
  GPIO_InitStruct.Pin = VCP_RX_Pin;
  GPIO_InitStruct.Mode = GPIO_MODE_AF_PP;
  GPIO_InitStruct.Pull = GPIO_NOPULL;
  GPIO_InitStruct.Speed = GPIO_SPEED_FREQ_LOW;
  GPIO_InitStruct.Alternate = GPIO_AF7_USART1;
  HAL_GPIO_Init(VCP_RX_GPIO_Port, &GPIO_InitStruct);

  /*Configure GPIO pin : QSPI_NCS_Pin */
  GPIO_InitStruct.Pin = QSPI_NCS_Pin;
  GPIO_InitStruct.Mode = GPIO_MODE_AF_PP;
  GPIO_InitStruct.Pull = GPIO_NOPULL;
  GPIO_InitStruct.Speed = GPIO_SPEED_FREQ_VERY_HIGH;
  GPIO_InitStruct.Alternate = GPIO_AF10_QUADSPI;
  HAL_GPIO_Init(QSPI_NCS_GPIO_Port, &GPIO_InitStruct);

  /*Configure GPIO pin : OTG_FS_VBUS_Pin */
  GPIO_InitStruct.Pin = OTG_FS_VBUS_Pin;
  GPIO_InitStruct.Mode = GPIO_MODE_INPUT;
  GPIO_InitStruct.Pull = GPIO_NOPULL;
  HAL_GPIO_Init(OTG_FS_VBUS_GPIO_Port, &GPIO_InitStruct);

  /*Configure GPIO pin : Audio_INT_Pin */
  GPIO_InitStruct.Pin = Audio_INT_Pin;
  GPIO_InitStruct.Mode = GPIO_MODE_EVT_RISING;
  GPIO_InitStruct.Pull = GPIO_NOPULL;
  HAL_GPIO_Init(Audio_INT_GPIO_Port, &GPIO_InitStruct);

  /*Configure GPIO pins : OTG_FS_P_Pin OTG_FS_N_Pin OTG_FS_ID_Pin */
  GPIO_InitStruct.Pin = OTG_FS_P_Pin|OTG_FS_N_Pin|OTG_FS_ID_Pin;
  GPIO_InitStruct.Mode = GPIO_MODE_AF_PP;
  GPIO_InitStruct.Pull = GPIO_NOPULL;
  GPIO_InitStruct.Speed = GPIO_SPEED_FREQ_VERY_HIGH;
  GPIO_InitStruct.Alternate = GPIO_AF10_OTG_FS;
  HAL_GPIO_Init(GPIOA, &GPIO_InitStruct);

  /*Configure GPIO pins : SAI2_MCLKA_Pin SAI2_SCKA_Pin SAI2_FSA_Pin SAI2_SDA_Pin */
  GPIO_InitStruct.Pin = SAI2_MCLKA_Pin|SAI2_SCKA_Pin|SAI2_FSA_Pin|SAI2_SDA_Pin;
  GPIO_InitStruct.Mode = GPIO_MODE_AF_PP;
  GPIO_InitStruct.Pull = GPIO_NOPULL;
  GPIO_InitStruct.Speed = GPIO_SPEED_FREQ_LOW;
  GPIO_InitStruct.Alternate = GPIO_AF10_SAI2;
  HAL_GPIO_Init(GPIOI, &GPIO_InitStruct);

  /*Configure GPIO pin : SAI2_SDB_Pin */
  GPIO_InitStruct.Pin = SAI2_SDB_Pin;
  GPIO_InitStruct.Mode = GPIO_MODE_AF_PP;
  GPIO_InitStruct.Pull = GPIO_NOPULL;
  GPIO_InitStruct.Speed = GPIO_SPEED_FREQ_LOW;
  GPIO_InitStruct.Alternate = GPIO_AF10_SAI2;
  HAL_GPIO_Init(SAI2_SDB_GPIO_Port, &GPIO_InitStruct);

  /*Configure GPIO pin : OTG_FS_PowerSwitchOn_Pin */
  GPIO_InitStruct.Pin = OTG_FS_PowerSwitchOn_Pin;
  GPIO_InitStruct.Mode = GPIO_MODE_OUTPUT_PP;
  GPIO_InitStruct.Pull = GPIO_NOPULL;
  GPIO_InitStruct.Speed = GPIO_SPEED_FREQ_LOW;
  HAL_GPIO_Init(OTG_FS_PowerSwitchOn_GPIO_Port, &GPIO_InitStruct);

  /*Configure GPIO pin : DCMI_D5_Pin */
  GPIO_InitStruct.Pin = DCMI_D5_Pin;
  GPIO_InitStruct.Mode = GPIO_MODE_AF_PP;
  GPIO_InitStruct.Pull = GPIO_NOPULL;
  GPIO_InitStruct.Speed = GPIO_SPEED_FREQ_LOW;
  GPIO_InitStruct.Alternate = GPIO_AF13_DCMI;
  HAL_GPIO_Init(DCMI_D5_GPIO_Port, &GPIO_InitStruct);

  /*Configure GPIO pins : ARDUINO_D7_Pin ARDUINO_D8_Pin LCD_DISP_Pin */
  GPIO_InitStruct.Pin = ARDUINO_D7_Pin|ARDUINO_D8_Pin|LCD_DISP_Pin;
  GPIO_InitStruct.Mode = GPIO_MODE_OUTPUT_PP;
  GPIO_InitStruct.Pull = GPIO_NOPULL;
  GPIO_InitStruct.Speed = GPIO_SPEED_FREQ_LOW;
  HAL_GPIO_Init(GPIOI, &GPIO_InitStruct);

  /*Configure GPIO pin : uSD_Detect_Pin */
  GPIO_InitStruct.Pin = uSD_Detect_Pin;
  GPIO_InitStruct.Mode = GPIO_MODE_INPUT;
  GPIO_InitStruct.Pull = GPIO_NOPULL;
  HAL_GPIO_Init(uSD_Detect_GPIO_Port, &GPIO_InitStruct);

  /*Configure GPIO pin : LCD_BL_CTRL_Pin */
  GPIO_InitStruct.Pin = LCD_BL_CTRL_Pin;
  GPIO_InitStruct.Mode = GPIO_MODE_OUTPUT_PP;
  GPIO_InitStruct.Pull = GPIO_NOPULL;
  GPIO_InitStruct.Speed = GPIO_SPEED_FREQ_LOW;
  HAL_GPIO_Init(LCD_BL_CTRL_GPIO_Port, &GPIO_InitStruct);

  /*Configure GPIO pin : DCMI_VSYNC_Pin */
  GPIO_InitStruct.Pin = DCMI_VSYNC_Pin;
  GPIO_InitStruct.Mode = GPIO_MODE_AF_PP;
  GPIO_InitStruct.Pull = GPIO_NOPULL;
  GPIO_InitStruct.Speed = GPIO_SPEED_FREQ_LOW;
  GPIO_InitStruct.Alternate = GPIO_AF13_DCMI;
  HAL_GPIO_Init(DCMI_VSYNC_GPIO_Port, &GPIO_InitStruct);

  /*Configure GPIO pin : OTG_FS_OverCurrent_Pin */
  GPIO_InitStruct.Pin = OTG_FS_OverCurrent_Pin;
  GPIO_InitStruct.Mode = GPIO_MODE_INPUT;
  GPIO_InitStruct.Pull = GPIO_NOPULL;
  HAL_GPIO_Init(OTG_FS_OverCurrent_GPIO_Port, &GPIO_InitStruct);

  /*Configure GPIO pins : TP3_Pin NC2_Pin */
  GPIO_InitStruct.Pin = TP3_Pin|NC2_Pin;
  GPIO_InitStruct.Mode = GPIO_MODE_INPUT;
  GPIO_InitStruct.Pull = GPIO_NOPULL;
  HAL_GPIO_Init(GPIOH, &GPIO_InitStruct);

  /*Configure GPIO pin : ARDUINO_SCK_D13_Pin */
  GPIO_InitStruct.Pin = ARDUINO_SCK_D13_Pin;
  GPIO_InitStruct.Mode = GPIO_MODE_AF_PP;
  GPIO_InitStruct.Pull = GPIO_NOPULL;
  GPIO_InitStruct.Speed = GPIO_SPEED_FREQ_LOW;
  GPIO_InitStruct.Alternate = GPIO_AF5_SPI2;
  HAL_GPIO_Init(ARDUINO_SCK_D13_GPIO_Port, &GPIO_InitStruct);

  /*Configure GPIO pin : DCMI_PWR_EN_Pin */
  GPIO_InitStruct.Pin = DCMI_PWR_EN_Pin;
  GPIO_InitStruct.Mode = GPIO_MODE_OUTPUT_PP;
  GPIO_InitStruct.Pull = GPIO_NOPULL;
  GPIO_InitStruct.Speed = GPIO_SPEED_FREQ_LOW;
  HAL_GPIO_Init(DCMI_PWR_EN_GPIO_Port, &GPIO_InitStruct);

  /*Configure GPIO pins : DCMI_D4_Pin DCMI_D3_Pin DCMI_D0_Pin DCMI_D2_Pin
                           DCMI_D1_Pin */
  GPIO_InitStruct.Pin = DCMI_D4_Pin|DCMI_D3_Pin|DCMI_D0_Pin|DCMI_D2_Pin
                          |DCMI_D1_Pin;
  GPIO_InitStruct.Mode = GPIO_MODE_AF_PP;
  GPIO_InitStruct.Pull = GPIO_NOPULL;
  GPIO_InitStruct.Speed = GPIO_SPEED_FREQ_LOW;
  GPIO_InitStruct.Alternate = GPIO_AF13_DCMI;
  HAL_GPIO_Init(GPIOH, &GPIO_InitStruct);

  /*Configure GPIO pin : ARDUINO_PWM_CS_D5_Pin */
  GPIO_InitStruct.Pin = ARDUINO_PWM_CS_D5_Pin;
  GPIO_InitStruct.Mode = GPIO_MODE_AF_PP;
  GPIO_InitStruct.Pull = GPIO_NOPULL;
  GPIO_InitStruct.Speed = GPIO_SPEED_FREQ_LOW;
  GPIO_InitStruct.Alternate = GPIO_AF2_TIM5;
  HAL_GPIO_Init(ARDUINO_PWM_CS_D5_GPIO_Port, &GPIO_InitStruct);

  /*Configure GPIO pin : VCP_TX_Pin */
  GPIO_InitStruct.Pin = VCP_TX_Pin;
  GPIO_InitStruct.Mode = GPIO_MODE_AF_PP;
  GPIO_InitStruct.Pull = GPIO_NOPULL;
  GPIO_InitStruct.Speed = GPIO_SPEED_FREQ_LOW;
  GPIO_InitStruct.Alternate = GPIO_AF7_USART1;
  HAL_GPIO_Init(VCP_TX_GPIO_Port, &GPIO_InitStruct);

  /*Configure GPIO pin : ARDUINO_PWM_D10_Pin */
  GPIO_InitStruct.Pin = ARDUINO_PWM_D10_Pin;
  GPIO_InitStruct.Mode = GPIO_MODE_AF_PP;
  GPIO_InitStruct.Pull = GPIO_NOPULL;
  GPIO_InitStruct.Speed = GPIO_SPEED_FREQ_LOW;
  GPIO_InitStruct.Alternate = GPIO_AF1_TIM1;
  HAL_GPIO_Init(ARDUINO_PWM_D10_GPIO_Port, &GPIO_InitStruct);

  /*Configure GPIO pin : LCD_INT_Pin */
  GPIO_InitStruct.Pin = LCD_INT_Pin;
  GPIO_InitStruct.Mode = GPIO_MODE_EVT_RISING;
  GPIO_InitStruct.Pull = GPIO_NOPULL;
  HAL_GPIO_Init(LCD_INT_GPIO_Port, &GPIO_InitStruct);

  /*Configure GPIO pin : ULPI_NXT_Pin */
  GPIO_InitStruct.Pin = ULPI_NXT_Pin;
  GPIO_InitStruct.Mode = GPIO_MODE_AF_PP;
  GPIO_InitStruct.Pull = GPIO_NOPULL;
  GPIO_InitStruct.Speed = GPIO_SPEED_FREQ_VERY_HIGH;
  GPIO_InitStruct.Alternate = GPIO_AF10_OTG_HS;
  HAL_GPIO_Init(ULPI_NXT_GPIO_Port, &GPIO_InitStruct);

  /*Configure GPIO pins : ARDUINO_D4_Pin ARDUINO_D2_Pin EXT_RST_Pin */
  GPIO_InitStruct.Pin = ARDUINO_D4_Pin|ARDUINO_D2_Pin|EXT_RST_Pin;
  GPIO_InitStruct.Mode = GPIO_MODE_OUTPUT_PP;
  GPIO_InitStruct.Pull = GPIO_NOPULL;
  GPIO_InitStruct.Speed = GPIO_SPEED_FREQ_LOW;
  HAL_GPIO_Init(GPIOG, &GPIO_InitStruct);

  /*Configure GPIO pins : ARDUINO_A4_Pin ARDUINO_A5_Pin ARDUINO_A1_Pin ARDUINO_A2_Pin
                           ARDUINO_A3_Pin */
  GPIO_InitStruct.Pin = ARDUINO_A4_Pin|ARDUINO_A5_Pin|ARDUINO_A1_Pin|ARDUINO_A2_Pin
                          |ARDUINO_A3_Pin;
  GPIO_InitStruct.Mode = GPIO_MODE_ANALOG;
  GPIO_InitStruct.Pull = GPIO_NOPULL;
  HAL_GPIO_Init(GPIOF, &GPIO_InitStruct);

  /*Configure GPIO pins : ULPI_STP_Pin ULPI_DIR_Pin */
  GPIO_InitStruct.Pin = ULPI_STP_Pin|ULPI_DIR_Pin;
  GPIO_InitStruct.Mode = GPIO_MODE_AF_PP;
  GPIO_InitStruct.Pull = GPIO_NOPULL;
  GPIO_InitStruct.Speed = GPIO_SPEED_FREQ_VERY_HIGH;
  GPIO_InitStruct.Alternate = GPIO_AF10_OTG_HS;
  HAL_GPIO_Init(GPIOC, &GPIO_InitStruct);

  /*Configure GPIO pins : RMII_MDC_Pin RMII_RXD0_Pin RMII_RXD1_Pin */
  GPIO_InitStruct.Pin = RMII_MDC_Pin|RMII_RXD0_Pin|RMII_RXD1_Pin;
  GPIO_InitStruct.Mode = GPIO_MODE_AF_PP;
  GPIO_InitStruct.Pull = GPIO_NOPULL;
  GPIO_InitStruct.Speed = GPIO_SPEED_FREQ_VERY_HIGH;
  GPIO_InitStruct.Alternate = GPIO_AF11_ETH;
  HAL_GPIO_Init(GPIOC, &GPIO_InitStruct);

  /*Configure GPIO pin : PB2 */
  GPIO_InitStruct.Pin = GPIO_PIN_2;
  GPIO_InitStruct.Mode = GPIO_MODE_AF_PP;
  GPIO_InitStruct.Pull = GPIO_NOPULL;
  GPIO_InitStruct.Speed = GPIO_SPEED_FREQ_VERY_HIGH;
  GPIO_InitStruct.Alternate = GPIO_AF9_QUADSPI;
  HAL_GPIO_Init(GPIOB, &GPIO_InitStruct);

  /*Configure GPIO pins : QSPI_D1_Pin QSPI_D3_Pin QSPI_D0_Pin */
  GPIO_InitStruct.Pin = QSPI_D1_Pin|QSPI_D3_Pin|QSPI_D0_Pin;
  GPIO_InitStruct.Mode = GPIO_MODE_AF_PP;
  GPIO_InitStruct.Pull = GPIO_NOPULL;
  GPIO_InitStruct.Speed = GPIO_SPEED_FREQ_VERY_HIGH;
  GPIO_InitStruct.Alternate = GPIO_AF9_QUADSPI;
  HAL_GPIO_Init(GPIOD, &GPIO_InitStruct);

  /*Configure GPIO pin : RMII_RXER_Pin */
  GPIO_InitStruct.Pin = RMII_RXER_Pin;
  GPIO_InitStruct.Mode = GPIO_MODE_INPUT;
  GPIO_InitStruct.Pull = GPIO_NOPULL;
  HAL_GPIO_Init(RMII_RXER_GPIO_Port, &GPIO_InitStruct);

  /*Configure GPIO pins : RMII_REF_CLK_Pin RMII_MDIO_Pin RMII_CRS_DV_Pin */
  GPIO_InitStruct.Pin = RMII_REF_CLK_Pin|RMII_MDIO_Pin|RMII_CRS_DV_Pin;
  GPIO_InitStruct.Mode = GPIO_MODE_AF_PP;
  GPIO_InitStruct.Pull = GPIO_NOPULL;
  GPIO_InitStruct.Speed = GPIO_SPEED_FREQ_VERY_HIGH;
  GPIO_InitStruct.Alternate = GPIO_AF11_ETH;
  HAL_GPIO_Init(GPIOA, &GPIO_InitStruct);

  /*Configure GPIO pin : ARDUINO_A0_Pin */
  GPIO_InitStruct.Pin = ARDUINO_A0_Pin;
  GPIO_InitStruct.Mode = GPIO_MODE_ANALOG;
  GPIO_InitStruct.Pull = GPIO_NOPULL;
  HAL_GPIO_Init(ARDUINO_A0_GPIO_Port, &GPIO_InitStruct);

  /*Configure GPIO pins : DCMI_HSYNC_Pin PA6 */
  GPIO_InitStruct.Pin = DCMI_HSYNC_Pin|GPIO_PIN_6;
  GPIO_InitStruct.Mode = GPIO_MODE_AF_PP;
  GPIO_InitStruct.Pull = GPIO_NOPULL;
  GPIO_InitStruct.Speed = GPIO_SPEED_FREQ_LOW;
  GPIO_InitStruct.Alternate = GPIO_AF13_DCMI;
  HAL_GPIO_Init(GPIOA, &GPIO_InitStruct);

  /*Configure GPIO pins : LCD_SCL_Pin LCD_SDA_Pin */
  GPIO_InitStruct.Pin = LCD_SCL_Pin|LCD_SDA_Pin;
  GPIO_InitStruct.Mode = GPIO_MODE_AF_OD;
  GPIO_InitStruct.Pull = GPIO_NOPULL;
  GPIO_InitStruct.Speed = GPIO_SPEED_FREQ_VERY_HIGH;
  GPIO_InitStruct.Alternate = GPIO_AF4_I2C3;
  HAL_GPIO_Init(GPIOH, &GPIO_InitStruct);

  /*Configure GPIO pins : ULPI_CLK_Pin ULPI_D0_Pin */
  GPIO_InitStruct.Pin = ULPI_CLK_Pin|ULPI_D0_Pin;
  GPIO_InitStruct.Mode = GPIO_MODE_AF_PP;
  GPIO_InitStruct.Pull = GPIO_NOPULL;
  GPIO_InitStruct.Speed = GPIO_SPEED_FREQ_VERY_HIGH;
  GPIO_InitStruct.Alternate = GPIO_AF10_OTG_HS;
  HAL_GPIO_Init(GPIOA, &GPIO_InitStruct);

  /*Configure GPIO pin : ARDUINO_PWM_D6_Pin */
  GPIO_InitStruct.Pin = ARDUINO_PWM_D6_Pin;
  GPIO_InitStruct.Mode = GPIO_MODE_AF_PP;
  GPIO_InitStruct.Pull = GPIO_NOPULL;
  GPIO_InitStruct.Speed = GPIO_SPEED_FREQ_LOW;
  GPIO_InitStruct.Alternate = GPIO_AF9_TIM12;
  HAL_GPIO_Init(ARDUINO_PWM_D6_GPIO_Port, &GPIO_InitStruct);

  /*Configure GPIO pins : ARDUINO_MISO_D12_Pin ARDUINO_MOSI_PWM_D11_Pin */
  GPIO_InitStruct.Pin = ARDUINO_MISO_D12_Pin|ARDUINO_MOSI_PWM_D11_Pin;
  GPIO_InitStruct.Mode = GPIO_MODE_AF_PP;
  GPIO_InitStruct.Pull = GPIO_NOPULL;
  GPIO_InitStruct.Speed = GPIO_SPEED_FREQ_LOW;
  GPIO_InitStruct.Alternate = GPIO_AF5_SPI2;
  HAL_GPIO_Init(GPIOB, &GPIO_InitStruct);

}

/* USER CODE BEGIN 4 */

void LCD_GPIO_Init(LTDC_HandleTypeDef *hltdc, void *Params)
{
	GPIO_InitTypeDef gpio_init_structure;
	/* Enable the LTDC and DMA2D clocks */
	__HAL_RCC_LTDC_CLK_ENABLE();
	__HAL_RCC_DMA2D_CLK_ENABLE();
	/* Enable GPIOs clock */
	__HAL_RCC_GPIOE_CLK_ENABLE();
	__HAL_RCC_GPIOG_CLK_ENABLE();
	__HAL_RCC_GPIOI_CLK_ENABLE();
	__HAL_RCC_GPIOJ_CLK_ENABLE();
	__HAL_RCC_GPIOK_CLK_ENABLE();
	/*** LTDC Pins configuration ***/
	/* GPIOE configuration */
	gpio_init_structure.Pin = GPIO_PIN_4;
	gpio_init_structure.Mode = GPIO_MODE_AF_PP;
	gpio_init_structure.Pull = GPIO_NOPULL;
	gpio_init_structure.Speed = GPIO_SPEED_FAST;
	gpio_init_structure.Alternate = GPIO_AF14_LTDC; HAL_GPIO_Init(GPIOE, &gpio_init_structure);
	/* GPIOG configuration */
	gpio_init_structure.Pin = GPIO_PIN_12;
	gpio_init_structure.Mode = GPIO_MODE_AF_PP;
	gpio_init_structure.Alternate = GPIO_AF9_LTDC;
	HAL_GPIO_Init(GPIOG, &gpio_init_structure);
	/* GPIOI LTDC alternate configuration */
	gpio_init_structure.Pin = GPIO_PIN_9 | GPIO_PIN_10 | GPIO_PIN_13 | GPIO_PIN_14 | GPIO_PIN_15;
	gpio_init_structure.Mode = GPIO_MODE_AF_PP; gpio_init_structure.Alternate = GPIO_AF14_LTDC;
	HAL_GPIO_Init(GPIOI, &gpio_init_structure);
	/* GPIOJ configuration */
	gpio_init_structure.Pin = GPIO_PIN_0 | GPIO_PIN_1 | GPIO_PIN_2 |
			GPIO_PIN_3 | GPIO_PIN_4 | GPIO_PIN_5 | GPIO_PIN_6 | GPIO_PIN_7 | GPIO_PIN_5
			| GPIO_PIN_6 | GPIO_PIN_7 |GPIO_PIN_8 | GPIO_PIN_9 | GPIO_PIN_10 | GPIO_PIN_11 | GPIO_PIN_13 | GPIO_PIN_14 | GPIO_PIN_15;
	gpio_init_structure.Mode = GPIO_MODE_AF_PP;
	gpio_init_structure.Alternate = GPIO_AF14_LTDC;
	HAL_GPIO_Init(GPIOJ, &gpio_init_structure);
	/* GPIOK configuration */
	gpio_init_structure.Pin = GPIO_PIN_0 | GPIO_PIN_1 | GPIO_PIN_2 | GPIO_PIN_4 | GPIO_PIN_5 | GPIO_PIN_6 | GPIO_PIN_7;
	gpio_init_structure.Mode = GPIO_MODE_AF_PP;
	gpio_init_structure.Alternate = GPIO_AF14_LTDC;
	HAL_GPIO_Init(GPIOK, &gpio_init_structure);
	/* LCD_DISP GPIO configuration */
	gpio_init_structure.Pin = GPIO_PIN_12; /* LCD_DISP pin has to be manually controlled */
	gpio_init_structure.Mode = GPIO_MODE_OUTPUT_PP;
	HAL_GPIO_Init(GPIOI, &gpio_init_structure);
	/* LCD_BL_CTRL GPIO configuration */
	gpio_init_structure.Pin = GPIO_PIN_3; /* LCD_BL_CTRL pin has to be manually controlled */
	gpio_init_structure.Mode = GPIO_MODE_OUTPUT_PP;
	HAL_GPIO_Init(GPIOK, &gpio_init_structure);
}

//static void LTDC_Init(uint32_t FB_Address, uint16_t Xpos, uint16_t Ypos, uint16_t Width, uint16_t Height)
//{
//	/* Timing Configuration */
//	hltdc.Init.HorizontalSync = (RK043FN48H_HSYNC - 1);
//	hltdc.Init.VerticalSync = (RK043FN48H_VSYNC - 1);
//	hltdc.Init.AccumulatedHBP = (RK043FN48H_HSYNC + RK043FN48H_HBP - 1);
//	hltdc.Init.AccumulatedVBP = (RK043FN48H_VSYNC + RK043FN48H_VBP - 1);
//	hltdc.Init.AccumulatedActiveH = (RK043FN48H_HEIGHT + RK043FN48H_VSYNC + RK043FN48H_VBP - 1);
//	hltdc.Init.AccumulatedActiveW = (RK043FN48H_WIDTH + RK043FN48H_HSYNC + RK043FN48H_HBP - 1);
//	hltdc.Init.TotalHeigh = (RK043FN48H_HEIGHT + RK043FN48H_VSYNC + RK043FN48H_VBP + RK043FN48H_VFP - 1);
//	hltdc.Init.TotalWidth = (RK043FN48H_WIDTH + RK043FN48H_HSYNC + RK043FN48H_HBP + RK043FN48H_HFP - 1);
//
//	/* LCD clock configuration */
//	periph_clk_init_struct.PeriphClockSelection = RCC_PERIPHCLK_LTDC;
//	periph_clk_init_struct.PLLSAI.PLLSAIN = 192;
//	periph_clk_init_struct.PLLSAI.PLLSAIR = RK043FN48H_FREQUENCY_DIVIDER;
//	periph_clk_init_struct.PLLSAIDivR = RCC_PLLSAIDIVR_4;
//	HAL_RCCEx_PeriphCLKConfig(&periph_clk_init_struct);
//
//	/* Initialize the LCD pixel width and pixel height */
//	hltdc.LayerCfg->ImageWidth = RK043FN48H_WIDTH;
//	hltdc.LayerCfg->ImageHeight = RK043FN48H_HEIGHT;
//	hltdc.Init.Backcolor.Blue = 0;
//
//	/* Background value */
//	hltdc.Init.Backcolor.Green = 0;
//	hltdc.Init.Backcolor.Red = 0;
//
//	/* Polarity */
//	hltdc.Init.HSPolarity = LTDC_HSPOLARITY_AL;
//	hltdc.Init.VSPolarity = LTDC_VSPOLARITY_AL;
//	hltdc.Init.DEPolarity = LTDC_DEPOLARITY_AL;
//	hltdc.Init.PCPolarity = LTDC_PCPOLARITY_IPC;
//	hltdc.Instance = LTDC;
//	if(HAL_LTDC_GetState(&hltdc) == HAL_LTDC_STATE_RESET)
//	{
//		LCD_GPIO_Init(&hltdc, NULL);
//	}
//	HAL_LTDC_Init(&hltdc);
//
//	/* Assert display enable LCD_DISP pin */
//	HAL_GPIO_WritePin(GPIOI, GPIO_PIN_12, GPIO_PIN_SET);
//	/* Assert backlight LCD_BL_CTRL pin */
//	HAL_GPIO_WritePin(GPIOK, GPIO_PIN_3, GPIO_PIN_SET);
//	DrawProp[0].pFont = &Font24 ;
//	/* Layer Init */
//	layer_cfg.WindowX0 = Xpos;
//	layer_cfg.WindowX1 = Width;
//	layer_cfg.WindowY0 = Ypos;
//	layer_cfg.WindowY1 = Height;
//	layer_cfg.PixelFormat = LTDC_PIXEL_FORMAT_RGB565;
//	layer_cfg.FBStartAdress = FB_Address;
//	layer_cfg.Alpha = 255;
//	layer_cfg.Alpha0 = 0;
//	layer_cfg.Backcolor.Blue = 0;
//	layer_cfg.Backcolor.Green = 0;
//	layer_cfg.Backcolor.Red = 0;
//	layer_cfg.BlendingFactor1 = LTDC_BLENDING_FACTOR1_PAxCA;
//	layer_cfg.BlendingFactor2 = LTDC_BLENDING_FACTOR2_PAxCA;
//	layer_cfg.ImageWidth = Width;
//	layer_cfg.ImageHeight = Height;
//	HAL_LTDC_ConfigLayer(&hltdc, &layer_cfg, 1);
//
//	DrawProp[1].BackColor = ((uint32_t)0xFFFFFFFF);
//	DrawProp[1].pFont = &Font24;
//	DrawProp[1].TextColor = ((uint32_t)0xFF000000);
//}

/**
  * @brief  Jpeg Decode
  * @param  callback: line decoding callback
  * @param  file:     pointer to the jpg file
  * @param  width:    image width
  * @param  buff:     pointer to the image line
  * @retval None
  */
void jpeg_decode(JFILE *file, uint32_t width, uint8_t * buff, uint8_t (*callback)(uint8_t*, uint32_t))
{

  /* Decode JPEG Image */
  JSAMPROW buffer[2] = {0}; /* Output row buffer */
  uint32_t row_stride = 0; /* physical row width in image buffer */

  buffer[0] = buff;

  /* Step 1: allocate and initialize JPEG decompression object */
  cinfo.err = jpeg_std_error(&jerr);

  /* Initialize the JPEG decompression object */
  jpeg_create_decompress(&cinfo);

  jpeg_stdio_src (&cinfo, file);

  /* Step 3: read image parameters with jpeg_read_header() */
  jpeg_read_header(&cinfo, TRUE);

  /* Step 4: set parameters for decompression */
  cinfo.dct_method = JDCT_FLOAT;

  /* Step 5: start decompressor */
  jpeg_start_decompress(&cinfo);

  row_stride = width * 3;
  while (cinfo.output_scanline < cinfo.output_height)
  {
    (void) jpeg_read_scanlines(&cinfo, buffer, 1);

    if (callback(buffer[0], row_stride) != 0)
    {
      break;
    }
  }

  /* Step 6: Finish decompression */
  jpeg_finish_decompress(&cinfo);

  /* Step 7: Release JPEG decompression object */
  jpeg_destroy_decompress(&cinfo);

}

/**
  * @brief  LCD Configuration.
  * @Param  None
  * @retval None
  */
static void LCD_Config(void)
{
  /* Initialize the LCD */
  BSP_LCD_Init();

  /* Background Layer Initialization */
  BSP_LCD_LayerDefaultInit(0, LCD_FRAME_BUFFER);

  /* Set Foreground Layer */
  BSP_LCD_SelectLayer(0);

  /* Enable the LCD */
  BSP_LCD_DisplayOn();

  /* Set Display window */
  BSP_LCD_SetLayerWindow(0, 0, 0, IMAGE_WIDTH, IMAGE_HEIGHT);

  /* Clear the LCD Background layer */
  BSP_LCD_Clear(LCD_COLOR_WHITE);
}

/**
  * @brief  Copy decompressed data to display buffer.
  * @param  Row: Output row buffer
  * @param  DataLength: Row width in output buffer
  * @retval None
  */
static uint8_t Jpeg_CallbackFunction(uint8_t* Row, uint32_t DataLength)
{
#ifdef USE_DMA2D
  static DMA2D_HandleTypeDef hdma2d_eval;

  offset = (LCD_FRAME_BUFFER + (IMAGE_WIDTH * (IMAGE_HEIGHT - line_counter - 1) * 4));

/* Configure the DMA2D Mode, Color Mode and output offset */
  hdma2d_eval.Init.Mode         = DMA2D_M2M_PFC;
  hdma2d_eval.Init.ColorMode    = DMA2D_OUTPUT_ARGB8888;
  hdma2d_eval.Init.OutputOffset = 0;

  /* Foreground Configuration */
  hdma2d_eval.LayerCfg[1].AlphaMode = DMA2D_NO_MODIF_ALPHA;
  hdma2d_eval.LayerCfg[1].InputAlpha = 0xFF;
  hdma2d_eval.LayerCfg[1].InputColorMode = DMA2D_INPUT_RGB888;
  hdma2d_eval.LayerCfg[1].InputOffset = 0;

  hdma2d_eval.Instance = DMA2D;

  /* DMA2D Initialization */
  if(HAL_DMA2D_Init(&hdma2d_eval) == HAL_OK)
  {
    if(HAL_DMA2D_ConfigLayer(&hdma2d_eval, 1) == HAL_OK)
    {
      if (HAL_DMA2D_Start(&hdma2d_eval, (uint32_t)Row, (uint32_t)offset, IMAGE_WIDTH, 1) == HAL_OK)
      {
        /* Polling For DMA transfer */
        HAL_DMA2D_PollForTransfer(&hdma2d_eval, 10);
      }
    }
  }
#else /* DMA2D not used */
  RGB_matrix =  (RGB_typedef*)Row;
  uint32_t  ARGB32Buffer[IMAGE_WIDTH];
  uint32_t counter = 0;

  for(counter = 0; counter < IMAGE_WIDTH; counter++)
  {
    ARGB32Buffer[counter]  = (uint32_t)
    (
     ((RGB_matrix[counter].B << 16)|
      (RGB_matrix[counter].G << 8)|
      (RGB_matrix[counter].R) | 0xFF000000)
    );

    *(__IO uint32_t *)(LCD_FRAME_BUFFER + (counter*4) + (IMAGE_WIDTH * (IMAGE_HEIGHT - line_counter - 1) * 4)) = ARGB32Buffer[counter];
  }
#endif

#ifdef SWAP_RB
  uint32_t pixel = 0, width_counter, result = 0, result1 = 0;

   for(width_counter = 0; width_counter < IMAGE_WIDTH; width_counter++)
   {
     pixel = *(__IO uint32_t *)(LCD_FRAME_BUFFER + (width_counter*4) + (IMAGE_WIDTH * (IMAGE_HEIGHT - line_counter - 1) * 4));
     result1 = (((pixel & 0x00FF0000) >> 16) | ((pixel & 0x000000FF) << 16));
     pixel = pixel & 0xFF00FF00;
     result = (result1 | pixel);
     *(__IO uint32_t *)(LCD_FRAME_BUFFER + (width_counter*4) + (IMAGE_WIDTH * (IMAGE_HEIGHT - line_counter - 1) * 4)) = result;

   }
#endif

  line_counter--;
  return 0;
}

/* USER CODE END 4 */

void Error_Handler(void)
{
  __disable_irq();
  while (1)
  {
  }
}
